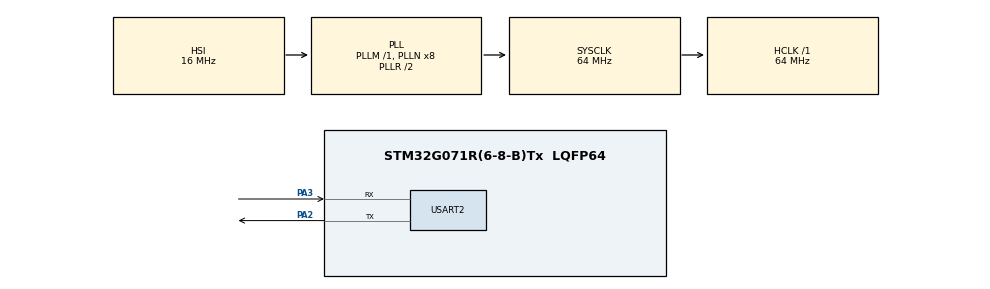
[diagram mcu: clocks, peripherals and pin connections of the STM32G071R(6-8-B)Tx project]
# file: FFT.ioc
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Mcu.Family=STM32G0
Mcu.Name=STM32G071R(6-8-B)Tx
Mcu.Package=LQFP64
PA13.Mode=Serial_Wire
PA13.Signal=SYS_SWDIO
PA14-BOOT0.Mode=Serial_Wire
PA14-BOOT0.Signal=SYS_SWCLK
PA2.Mode=Asynchronous
PA2.Signal=USART2_TX
PA3.Mode=Asynchronous
PA3.Signal=USART2_RX
ProjectManager.HeapSize=0x200
ProjectManager.StackSize=0x400
ProjectManager.TargetToolchain=STM32CubeIDE
RCC.ADCFreq_Value=64000000
RCC.AHBFreq_Value=64000000
RCC.CortexFreq_Value=64000000
RCC.EXTERNAL_CLOCK_VALUE=12288000
RCC.HCLKFreq_Value=64000000
RCC.HSE_VALUE=8000000
RCC.HSI_VALUE=16000000
RCC.SYSCLKFreq_VALUE=64000000
RCC.SYSCLKSource=RCC_SYSCLKSOURCE_PLLCLK
RCC.VCOOutputFreq_Value=128000000
USART2.VirtualMode-Asynchronous=VM_ASYNC
board=NUCLEO-G071RB

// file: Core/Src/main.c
/* USER CODE BEGIN Header */
/**
  ******************************************************************************
  * @file           : main.c
  * @brief          : Main program body
  ******************************************************************************
  * @attention
  *
  * Copyright (c) 2026 STMicroelectronics.
  * All rights reserved.
  *
  * This software is licensed under terms that can be found in the LICENSE file
  * in the root directory of this software component.
  * If no LICENSE file comes with this software, it is provided AS-IS.
  *
  ******************************************************************************
  */
/* USER CODE END Header */
#include "main.h"

/* USER CODE BEGIN Includes */
#include <stdio.h>
#define ARM_MATH_CM4
#include "arm_math.h"

/* USER CODE END Includes */

UART_HandleTypeDef huart2;

void SystemClock_Config(void);
static void MX_GPIO_Init(void);
static void MX_USART2_UART_Init(void);

/* USER CODE BEGIN 0 */
#define FFT_SIZE    1024
#define SAMPLING_RATE  320     // sampling rate
// Resolution 0.3125 Hz

float32_t magnitude_z[FFT_SIZE];
float32_t FFT_input_z[FFT_SIZE * 2];
float32_t FFT_output_z[FFT_SIZE * 2];

arm_cfft_radix4_instance_f32	FFThandler;

void calculateMagnitudeArray(float *input, float *output, int length) {
    for (int i = 0; i < length ; i++) {
        float real = input[2 * i];
        float imag = input[2 * i + 1];
        output[i] = sqrtf(real * real + imag * imag);
    }
}

int _write(int file, char *ptr, int len)
{
	HAL_UART_Transmit(&huart2,(uint8_t*)ptr,len,HAL_MAX_DELAY);  //If you need to use "printf" for displaying output
	return len;													   //If you need to use 'Transmit', you don't need to have..
}
/* USER CODE END 0 */

int main(void)
{

  /* USER CODE BEGIN 1 */
	arm_cfft_radix4_init_f32(&FFThandler, FFT_SIZE , 0, 1);
  /* USER CODE END 1 */

  /* MCU Configuration--------------------------------------------------------*/

  /* Reset of all peripherals, Initializes the Flash interface and the Systick. */
  HAL_Init();

  /* Configure the system clock */
  SystemClock_Config();

  /* Initialize all configured peripherals */
  MX_GPIO_Init();
  MX_USART2_UART_Init();
  /* USER CODE BEGIN 2 */

  for(int i = 0 ; i < FFT_SIZE ; i++){
	  FFT_input_z[i] = 2 * arm_sin_f32(2 * M_PI * 20 * i * 0.003125);
  }

	for (int i = 0; i < FFT_SIZE; i++) {

		FFT_output_z[2 * i] = FFT_input_z[i] ;   // real
		FFT_output_z[2 * i + 1] = 0.0f;          // imag

	}

  arm_cfft_radix4_f32(&FFThandler, FFT_output_z);
  arm_cmplx_mag_f32(FFT_output_z, magnitude_z, FFT_SIZE);

     for (int i = 1; i < FFT_SIZE / 2  ; i++) {
    	 magnitude_z[i] *=  2.0f / FFT_SIZE ;
    	 printf(" %.6f \r\n" ,  magnitude_z[i] );
	    	}

  /* USER CODE END 2 */

  /* Infinite loop */
  while (1)
  {

  }
}

void SystemClock_Config(void)
{
  RCC_OscInitTypeDef RCC_OscInitStruct = {0};
  RCC_ClkInitTypeDef RCC_ClkInitStruct = {0};

  /** Configure the main internal regulator output voltage
  */
  HAL_PWREx_ControlVoltageScaling(PWR_REGULATOR_VOLTAGE_SCALE1);

  /** Initializes the RCC Oscillators according to the specified parameters
  * in the RCC_OscInitTypeDef structure.
  */
  RCC_OscInitStruct.OscillatorType = RCC_OSCILLATORTYPE_HSI;
  RCC_OscInitStruct.HSIState = RCC_HSI_ON;
  RCC_OscInitStruct.HSIDiv = RCC_HSI_DIV1;
  RCC_OscInitStruct.HSICalibrationValue = RCC_HSICALIBRATION_DEFAULT;
  RCC_OscInitStruct.PLL.PLLState = RCC_PLL_ON;
  RCC_OscInitStruct.PLL.PLLSource = RCC_PLLSOURCE_HSI;
  RCC_OscInitStruct.PLL.PLLM = RCC_PLLM_DIV1;
  RCC_OscInitStruct.PLL.PLLN = 8;
  RCC_OscInitStruct.PLL.PLLP = RCC_PLLP_DIV2;
  RCC_OscInitStruct.PLL.PLLQ = RCC_PLLQ_DIV2;
  RCC_OscInitStruct.PLL.PLLR = RCC_PLLR_DIV2;
  if (HAL_RCC_OscConfig(&RCC_OscInitStruct) != HAL_OK)
  {
    Error_Handler();
  }

  /** Initializes the CPU, AHB and APB buses clocks
  */
  RCC_ClkInitStruct.ClockType = RCC_CLOCKTYPE_HCLK|RCC_CLOCKTYPE_SYSCLK
                              |RCC_CLOCKTYPE_PCLK1;
  RCC_ClkInitStruct.SYSCLKSource = RCC_SYSCLKSOURCE_PLLCLK;
  RCC_ClkInitStruct.AHBCLKDivider = RCC_SYSCLK_DIV1;
  RCC_ClkInitStruct.APB1CLKDivider = RCC_HCLK_DIV1;

  if (HAL_RCC_ClockConfig(&RCC_ClkInitStruct, FLASH_LATENCY_2) != HAL_OK)
  {
    Error_Handler();
  }
}

static void MX_USART2_UART_Init(void)
{

  huart2.Instance = USART2;
  huart2.Init.BaudRate = 115200;
  huart2.Init.WordLength = UART_WORDLENGTH_8B;
  huart2.Init.StopBits = UART_STOPBITS_1;
  huart2.Init.Parity = UART_PARITY_NONE;
  huart2.Init.Mode = UART_MODE_TX_RX;
  huart2.Init.HwFlowCtl = UART_HWCONTROL_NONE;
  huart2.Init.OverSampling = UART_OVERSAMPLING_16;
  huart2.Init.OneBitSampling = UART_ONE_BIT_SAMPLE_DISABLE;
  huart2.Init.ClockPrescaler = UART_PRESCALER_DIV1;
  huart2.AdvancedInit.AdvFeatureInit = UART_ADVFEATURE_NO_INIT;
  if (HAL_UART_Init(&huart2) != HAL_OK)
  {
    Error_Handler();
  }
  if (HAL_UARTEx_SetTxFifoThreshold(&huart2, UART_TXFIFO_THRESHOLD_1_8) != HAL_OK)
  {
    Error_Handler();
  }
  if (HAL_UARTEx_SetRxFifoThreshold(&huart2, UART_RXFIFO_THRESHOLD_1_8) != HAL_OK)
  {
    Error_Handler();
  }
  if (HAL_UARTEx_DisableFifoMode(&huart2) != HAL_OK)
  {
    Error_Handler();
  }

}

static void MX_GPIO_Init(void)
{

  /* GPIO Ports Clock Enable */
  __HAL_RCC_GPIOA_CLK_ENABLE();

}

void Error_Handler(void)
{
  __disable_irq();
  while (1)
  {
  }
}
